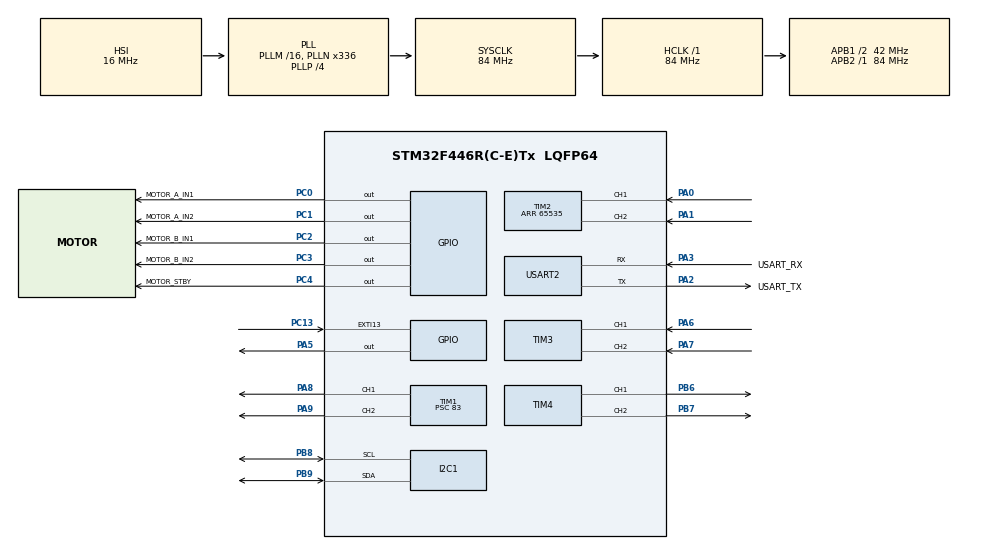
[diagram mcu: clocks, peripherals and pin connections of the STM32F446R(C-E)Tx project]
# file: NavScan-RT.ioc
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FREERTOS.Tasks01=defaultTask,24,128,StartDefaultTask,Default,NULL,Dynamic,NULL,NULL
Mcu.Family=STM32F4
Mcu.Name=STM32F446R(C-E)Tx
Mcu.Package=LQFP64
NUCLEO-F446RE.BUTTON=1
NUCLEO-F446RE.Bsp_Common_DEMO=true
NUCLEO-F446RE.LD1=true
NVIC.EXTI15_10_IRQn=true\:5\:0\:false\:false\:true\:true\:false\:true\:true
NVIC.PriorityGroup=NVIC_PRIORITYGROUP_4
NVIC.TIM6_DAC_IRQn=true\:15\:0\:false\:false\:true\:false\:false\:true\:true
NVIC.TimeBase=TIM6_DAC_IRQn
NVIC.TimeBaseIP=TIM6
PA0-WKUP.Signal=S_TIM2_CH1_ETR
PA1.Signal=S_TIM2_CH2
PA13.GPIO_Label=TMS
PA13.Mode=Serial_Wire
PA13.Signal=SYS_JTMS-SWDIO
PA14.GPIO_Label=TCK
PA14.Mode=Serial_Wire
PA14.Signal=SYS_JTCK-SWCLK
PA2.GPIO_Label=USART_TX
PA2.Mode=Asynchronous
PA2.Signal=USART2_TX
PA3.GPIO_Label=USART_RX
PA3.Mode=Asynchronous
PA3.Signal=USART2_RX
PA5.Signal=GPIO_Output
PA6.Signal=S_TIM3_CH1
PA7.Signal=S_TIM3_CH2
PA8.Signal=S_TIM1_CH1
PA9.Signal=S_TIM1_CH2
PB3.GPIO_Label=SWO
PB3.Signal=SYS_JTDO-SWO
PB6.Signal=S_TIM4_CH1
PB7.Signal=S_TIM4_CH2
PB8.Mode=I2C
PB8.Signal=I2C1_SCL
PB9.Mode=I2C
PB9.Signal=I2C1_SDA
PC0.GPIO_Label=MOTOR_A_IN1
PC0.Signal=GPIO_Output
PC1.GPIO_Label=MOTOR_A_IN2
PC1.Signal=GPIO_Output
PC13.Signal=GPXTI13
PC14-OSC32_IN.Signal=RCC_OSC32_IN
PC15-OSC32_OUT.Signal=RCC_OSC32_OUT
PC2.GPIO_Label=MOTOR_B_IN1
PC2.Signal=GPIO_Output
PC3.GPIO_Label=MOTOR_B_IN2
PC3.Signal=GPIO_Output
PC4.GPIO_Label=MOTOR_STBY
PC4.Signal=GPIO_Output
PH0-OSC_IN.Signal=RCC_OSC_IN
PH1-OSC_OUT.Signal=RCC_OSC_OUT
ProjectManager.HeapSize=0x200
ProjectManager.StackSize=0x400
ProjectManager.TargetToolchain=CMake
RCC.AHBFreq_Value=84000000
RCC.APB1CLKDivider=RCC_HCLK_DIV2
RCC.APB1Freq_Value=42000000
RCC.APB1TimFreq_Value=84000000
RCC.APB2Freq_Value=84000000
RCC.APB2TimFreq_Value=84000000
RCC.CortexFreq_Value=84000000
RCC.FLatency-AdvancedSettings=FLASH_LATENCY_2
RCC.HCLKFreq_Value=84000000
RCC.HSE_VALUE=8000000
RCC.HSI_VALUE=16000000
RCC.LSE_VALUE=32768
RCC.PLLN=336
RCC.PLLP=RCC_PLLP_DIV4
RCC.SYSCLKFreq_VALUE=84000000
RCC.SYSCLKSource=RCC_SYSCLKSOURCE_PLLCLK
RCC.USBFreq_Value=168000000
RCC.VCOOutputFreq_Value=336000000
SH.S_TIM1_CH1.0=TIM1_CH1,PWM Generation1 CH1
SH.S_TIM1_CH2.0=TIM1_CH2,PWM Generation2 CH2
SH.S_TIM2_CH1_ETR.0=TIM2_CH1,Encoder_Interface
SH.S_TIM2_CH2.0=TIM2_CH2,Encoder_Interface
SH.S_TIM3_CH1.0=TIM3_CH1,Encoder_Interface
SH.S_TIM3_CH2.0=TIM3_CH2,Encoder_Interface
SH.S_TIM4_CH1.0=TIM4_CH1,PWM Generation1 CH1
SH.S_TIM4_CH2.0=TIM4_CH2,PWM Generation2 CH2
TIM1.Channel-PWM\ Generation1\ CH1=TIM_CHANNEL_1
TIM1.Channel-PWM\ Generation2\ CH2=TIM_CHANNEL_2
TIM1.Period=19999
TIM1.Prescaler=83
TIM1.Pulse-PWM\ Generation1\ CH1=1500
TIM1.Pulse-PWM\ Generation2\ CH2=1500
TIM2.EncoderMode=TIM_ENCODERMODE_TI12
TIM2.Period=65535
TIM3.EncoderMode=TIM_ENCODERMODE_TI12
TIM4.Channel-PWM\ Generation1\ CH1=TIM_CHANNEL_1
TIM4.Channel-PWM\ Generation2\ CH2=TIM_CHANNEL_2
USART2.VirtualMode=VM_ASYNC
VP_FREERTOS_VS_CMSIS_V2.Mode=CMSIS_V2
VP_NUCLEO-F446RE_VS_BSP_COMMON.Mode=COMMON
VP_SYS_VS_tim6.Mode=TIM6
VP_TIM1_VS_ClockSourceINT.Mode=Internal
VP_TIM4_VS_ClockSourceINT.Mode=Internal
board=NUCLEO-F446RE

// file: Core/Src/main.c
/* USER CODE BEGIN Header */
/**
  ******************************************************************************
  * @file           : main.c
  * @brief          : Main program body
  ******************************************************************************
  * @attention
  *
  * Copyright (c) 2026 STMicroelectronics.
  * All rights reserved.
  *
  * This software is licensed under terms that can be found in the LICENSE file
  * in the root directory of this software component.
  * If no LICENSE file comes with this software, it is provided AS-IS.
  *
  ******************************************************************************
  */
/* USER CODE END Header */
#include "main.h"
#include "cmsis_os.h"

/* USER CODE BEGIN Includes */
#include "app.h"

/* Button state */
#define BUTTON_RELEASED                    0U
#define BUTTON_PRESSED                     1U

__IO uint32_t BspButtonState = BUTTON_RELEASED;
I2C_HandleTypeDef hi2c1;

TIM_HandleTypeDef htim1;
TIM_HandleTypeDef htim2;
TIM_HandleTypeDef htim3;
TIM_HandleTypeDef htim4;

UART_HandleTypeDef huart2;

/* Definitions for defaultTask */
osThreadId_t defaultTaskHandle;
const osThreadAttr_t defaultTask_attributes = {
  .name = "defaultTask",
  .stack_size = 128 * 4,
  .priority = (osPriority_t) osPriorityNormal,
};

void SystemClock_Config(void);
static void MX_GPIO_Init(void);
static void MX_I2C1_Init(void);
static void MX_TIM1_Init(void);
static void MX_TIM2_Init(void);
static void MX_TIM3_Init(void);
static void MX_TIM4_Init(void);
static void MX_USART2_UART_Init(void);
void StartDefaultTask(void *argument);

int main(void)
{

  /* MCU Configuration--------------------------------------------------------*/

  /* Reset of all peripherals, Initializes the Flash interface and the Systick. */
  HAL_Init();

  /* Configure the system clock */
  SystemClock_Config();

  /* Initialize all configured peripherals */
  MX_GPIO_Init();
  MX_I2C1_Init();
  MX_TIM1_Init();
  MX_TIM2_Init();
  MX_TIM3_Init();
  MX_TIM4_Init();
  MX_USART2_UART_Init();

  /* Init scheduler */
  osKernelInitialize();

  /* Create the thread(s) */
  /* creation of defaultTask */
  defaultTaskHandle = osThreadNew(StartDefaultTask, NULL, &defaultTask_attributes);

  /* Initialize leds */
  BSP_LED_Init(LED2);

  /* Initialize USER push-button, will be used to trigger an interrupt each time it's pressed.*/
  BSP_PB_Init(BUTTON_USER, BUTTON_MODE_EXTI);

  /* USER CODE END BSP */

  /* Start scheduler */
  osKernelStart();

  /* We should never get here as control is now taken by the scheduler */

  /* Infinite loop */
  /* USER CODE BEGIN WHILE */
  while (1)
  {

    /* -- Sample board code for User push-button in interrupt mode ---- */
    if (BspButtonState == BUTTON_PRESSED)
    {
      /* Update button state */
      BspButtonState = BUTTON_RELEASED;
      /* -- Sample board code to toggle leds ---- */
      BSP_LED_Toggle(LED2);
      /* ..... Perform your action ..... */
    }
    /* USER CODE END WHILE */

  }
}

void SystemClock_Config(void)
{
  RCC_OscInitTypeDef RCC_OscInitStruct = {0};
  RCC_ClkInitTypeDef RCC_ClkInitStruct = {0};

  /** Configure the main internal regulator output voltage
  */
  __HAL_RCC_PWR_CLK_ENABLE();
  __HAL_PWR_VOLTAGESCALING_CONFIG(PWR_REGULATOR_VOLTAGE_SCALE3);

  /** Initializes the RCC Oscillators according to the specified parameters
  * in the RCC_OscInitTypeDef structure.
  */
  RCC_OscInitStruct.OscillatorType = RCC_OSCILLATORTYPE_HSI;
  RCC_OscInitStruct.HSIState = RCC_HSI_ON;
  RCC_OscInitStruct.HSICalibrationValue = RCC_HSICALIBRATION_DEFAULT;
  RCC_OscInitStruct.PLL.PLLState = RCC_PLL_ON;
  RCC_OscInitStruct.PLL.PLLSource = RCC_PLLSOURCE_HSI;
  RCC_OscInitStruct.PLL.PLLM = 16;
  RCC_OscInitStruct.PLL.PLLN = 336;
  RCC_OscInitStruct.PLL.PLLP = RCC_PLLP_DIV4;
  RCC_OscInitStruct.PLL.PLLQ = 2;
  RCC_OscInitStruct.PLL.PLLR = 2;
  if (HAL_RCC_OscConfig(&RCC_OscInitStruct) != HAL_OK)
  {
    Error_Handler();
  }

  /** Initializes the CPU, AHB and APB buses clocks
  */
  RCC_ClkInitStruct.ClockType = RCC_CLOCKTYPE_HCLK|RCC_CLOCKTYPE_SYSCLK
                              |RCC_CLOCKTYPE_PCLK1|RCC_CLOCKTYPE_PCLK2;
  RCC_ClkInitStruct.SYSCLKSource = RCC_SYSCLKSOURCE_PLLCLK;
  RCC_ClkInitStruct.AHBCLKDivider = RCC_SYSCLK_DIV1;
  RCC_ClkInitStruct.APB1CLKDivider = RCC_HCLK_DIV2;
  RCC_ClkInitStruct.APB2CLKDivider = RCC_HCLK_DIV1;

  if (HAL_RCC_ClockConfig(&RCC_ClkInitStruct, FLASH_LATENCY_2) != HAL_OK)
  {
    Error_Handler();
  }
}

static void MX_I2C1_Init(void)
{

  hi2c1.Instance = I2C1;
  hi2c1.Init.ClockSpeed = 100000;
  hi2c1.Init.DutyCycle = I2C_DUTYCYCLE_2;
  hi2c1.Init.OwnAddress1 = 0;
  hi2c1.Init.AddressingMode = I2C_ADDRESSINGMODE_7BIT;
  hi2c1.Init.DualAddressMode = I2C_DUALADDRESS_DISABLE;
  hi2c1.Init.OwnAddress2 = 0;
  hi2c1.Init.GeneralCallMode = I2C_GENERALCALL_DISABLE;
  hi2c1.Init.NoStretchMode = I2C_NOSTRETCH_DISABLE;
  if (HAL_I2C_Init(&hi2c1) != HAL_OK)
  {
    Error_Handler();
  }

}

static void MX_TIM1_Init(void)
{

  TIM_ClockConfigTypeDef sClockSourceConfig = {0};
  TIM_MasterConfigTypeDef sMasterConfig = {0};
  TIM_OC_InitTypeDef sConfigOC = {0};
  TIM_BreakDeadTimeConfigTypeDef sBreakDeadTimeConfig = {0};

  htim1.Instance = TIM1;
  htim1.Init.Prescaler = 83;
  htim1.Init.CounterMode = TIM_COUNTERMODE_UP;
  htim1.Init.Period = 19999;
  htim1.Init.ClockDivision = TIM_CLOCKDIVISION_DIV1;
  htim1.Init.RepetitionCounter = 0;
  htim1.Init.AutoReloadPreload = TIM_AUTORELOAD_PRELOAD_DISABLE;
  if (HAL_TIM_Base_Init(&htim1) != HAL_OK)
  {
    Error_Handler();
  }
  sClockSourceConfig.ClockSource = TIM_CLOCKSOURCE_INTERNAL;
  if (HAL_TIM_ConfigClockSource(&htim1, &sClockSourceConfig) != HAL_OK)
  {
    Error_Handler();
  }
  if (HAL_TIM_PWM_Init(&htim1) != HAL_OK)
  {
    Error_Handler();
  }
  sMasterConfig.MasterOutputTrigger = TIM_TRGO_RESET;
  sMasterConfig.MasterSlaveMode = TIM_MASTERSLAVEMODE_DISABLE;
  if (HAL_TIMEx_MasterConfigSynchronization(&htim1, &sMasterConfig) != HAL_OK)
  {
    Error_Handler();
  }
  sConfigOC.OCMode = TIM_OCMODE_PWM1;
  sConfigOC.Pulse = 1500;
  sConfigOC.OCPolarity = TIM_OCPOLARITY_HIGH;
  sConfigOC.OCNPolarity = TIM_OCNPOLARITY_HIGH;
  sConfigOC.OCFastMode = TIM_OCFAST_DISABLE;
  sConfigOC.OCIdleState = TIM_OCIDLESTATE_RESET;
  sConfigOC.OCNIdleState = TIM_OCNIDLESTATE_RESET;
  if (HAL_TIM_PWM_ConfigChannel(&htim1, &sConfigOC, TIM_CHANNEL_1) != HAL_OK)
  {
    Error_Handler();
  }
  if (HAL_TIM_PWM_ConfigChannel(&htim1, &sConfigOC, TIM_CHANNEL_2) != HAL_OK)
  {
    Error_Handler();
  }
  sBreakDeadTimeConfig.OffStateRunMode = TIM_OSSR_DISABLE;
  sBreakDeadTimeConfig.OffStateIDLEMode = TIM_OSSI_DISABLE;
  sBreakDeadTimeConfig.LockLevel = TIM_LOCKLEVEL_OFF;
  sBreakDeadTimeConfig.DeadTime = 0;
  sBreakDeadTimeConfig.BreakState = TIM_BREAK_DISABLE;
  sBreakDeadTimeConfig.BreakPolarity = TIM_BREAKPOLARITY_HIGH;
  sBreakDeadTimeConfig.AutomaticOutput = TIM_AUTOMATICOUTPUT_DISABLE;
  if (HAL_TIMEx_ConfigBreakDeadTime(&htim1, &sBreakDeadTimeConfig) != HAL_OK)
  {
    Error_Handler();
  }
  HAL_TIM_MspPostInit(&htim1);

}

static void MX_TIM2_Init(void)
{

  TIM_Encoder_InitTypeDef sConfig = {0};
  TIM_MasterConfigTypeDef sMasterConfig = {0};

  htim2.Instance = TIM2;
  htim2.Init.Prescaler = 0;
  htim2.Init.CounterMode = TIM_COUNTERMODE_UP;
  htim2.Init.Period = 65535;
  htim2.Init.ClockDivision = TIM_CLOCKDIVISION_DIV1;
  htim2.Init.AutoReloadPreload = TIM_AUTORELOAD_PRELOAD_DISABLE;
  sConfig.EncoderMode = TIM_ENCODERMODE_TI12;
  sConfig.IC1Polarity = TIM_ICPOLARITY_RISING;
  sConfig.IC1Selection = TIM_ICSELECTION_DIRECTTI;
  sConfig.IC1Prescaler = TIM_ICPSC_DIV1;
  sConfig.IC1Filter = 0;
  sConfig.IC2Polarity = TIM_ICPOLARITY_RISING;
  sConfig.IC2Selection = TIM_ICSELECTION_DIRECTTI;
  sConfig.IC2Prescaler = TIM_ICPSC_DIV1;
  sConfig.IC2Filter = 0;
  if (HAL_TIM_Encoder_Init(&htim2, &sConfig) != HAL_OK)
  {
    Error_Handler();
  }
  sMasterConfig.MasterOutputTrigger = TIM_TRGO_RESET;
  sMasterConfig.MasterSlaveMode = TIM_MASTERSLAVEMODE_DISABLE;
  if (HAL_TIMEx_MasterConfigSynchronization(&htim2, &sMasterConfig) != HAL_OK)
  {
    Error_Handler();
  }

}

static void MX_TIM3_Init(void)
{

  TIM_Encoder_InitTypeDef sConfig = {0};
  TIM_MasterConfigTypeDef sMasterConfig = {0};

  htim3.Instance = TIM3;
  htim3.Init.Prescaler = 0;
  htim3.Init.CounterMode = TIM_COUNTERMODE_UP;
  htim3.Init.Period = 65535;
  htim3.Init.ClockDivision = TIM_CLOCKDIVISION_DIV1;
  htim3.Init.AutoReloadPreload = TIM_AUTORELOAD_PRELOAD_DISABLE;
  sConfig.EncoderMode = TIM_ENCODERMODE_TI12;
  sConfig.IC1Polarity = TIM_ICPOLARITY_RISING;
  sConfig.IC1Selection = TIM_ICSELECTION_DIRECTTI;
  sConfig.IC1Prescaler = TIM_ICPSC_DIV1;
  sConfig.IC1Filter = 0;
  sConfig.IC2Polarity = TIM_ICPOLARITY_RISING;
  sConfig.IC2Selection = TIM_ICSELECTION_DIRECTTI;
  sConfig.IC2Prescaler = TIM_ICPSC_DIV1;
  sConfig.IC2Filter = 0;
  if (HAL_TIM_Encoder_Init(&htim3, &sConfig) != HAL_OK)
  {
    Error_Handler();
  }
  sMasterConfig.MasterOutputTrigger = TIM_TRGO_RESET;
  sMasterConfig.MasterSlaveMode = TIM_MASTERSLAVEMODE_DISABLE;
  if (HAL_TIMEx_MasterConfigSynchronization(&htim3, &sMasterConfig) != HAL_OK)
  {
    Error_Handler();
  }

}

static void MX_TIM4_Init(void)
{

  TIM_ClockConfigTypeDef sClockSourceConfig = {0};
  TIM_MasterConfigTypeDef sMasterConfig = {0};
  TIM_OC_InitTypeDef sConfigOC = {0};

  htim4.Instance = TIM4;
  htim4.Init.Prescaler = 0;
  htim4.Init.CounterMode = TIM_COUNTERMODE_UP;
  htim4.Init.Period = 65535;
  htim4.Init.ClockDivision = TIM_CLOCKDIVISION_DIV1;
  htim4.Init.AutoReloadPreload = TIM_AUTORELOAD_PRELOAD_DISABLE;
  if (HAL_TIM_Base_Init(&htim4) != HAL_OK)
  {
    Error_Handler();
  }
  sClockSourceConfig.ClockSource = TIM_CLOCKSOURCE_INTERNAL;
  if (HAL_TIM_ConfigClockSource(&htim4, &sClockSourceConfig) != HAL_OK)
  {
    Error_Handler();
  }
  if (HAL_TIM_PWM_Init(&htim4) != HAL_OK)
  {
    Error_Handler();
  }
  sMasterConfig.MasterOutputTrigger = TIM_TRGO_RESET;
  sMasterConfig.MasterSlaveMode = TIM_MASTERSLAVEMODE_DISABLE;
  if (HAL_TIMEx_MasterConfigSynchronization(&htim4, &sMasterConfig) != HAL_OK)
  {
    Error_Handler();
  }
  sConfigOC.OCMode = TIM_OCMODE_PWM1;
  sConfigOC.Pulse = 0;
  sConfigOC.OCPolarity = TIM_OCPOLARITY_HIGH;
  sConfigOC.OCFastMode = TIM_OCFAST_DISABLE;
  if (HAL_TIM_PWM_ConfigChannel(&htim4, &sConfigOC, TIM_CHANNEL_1) != HAL_OK)
  {
    Error_Handler();
  }
  if (HAL_TIM_PWM_ConfigChannel(&htim4, &sConfigOC, TIM_CHANNEL_2) != HAL_OK)
  {
    Error_Handler();
  }
  HAL_TIM_MspPostInit(&htim4);

}

static void MX_USART2_UART_Init(void)
{

  huart2.Instance = USART2;
  huart2.Init.BaudRate = 115200;
  huart2.Init.WordLength = UART_WORDLENGTH_8B;
  huart2.Init.StopBits = UART_STOPBITS_1;
  huart2.Init.Parity = UART_PARITY_NONE;
  huart2.Init.Mode = UART_MODE_TX_RX;
  huart2.Init.HwFlowCtl = UART_HWCONTROL_NONE;
  huart2.Init.OverSampling = UART_OVERSAMPLING_16;
  if (HAL_UART_Init(&huart2) != HAL_OK)
  {
    Error_Handler();
  }

}

static void MX_GPIO_Init(void)
{
  GPIO_InitTypeDef GPIO_InitStruct = {0};

  /* GPIO Ports Clock Enable */
  __HAL_RCC_GPIOC_CLK_ENABLE();
  __HAL_RCC_GPIOH_CLK_ENABLE();
  __HAL_RCC_GPIOA_CLK_ENABLE();
  __HAL_RCC_GPIOB_CLK_ENABLE();

  /*Configure GPIO pin Output Level */
  HAL_GPIO_WritePin(GPIOC, MOTOR_A_IN1_Pin|MOTOR_A_IN2_Pin|MOTOR_B_IN1_Pin|MOTOR_B_IN2_Pin
                          |MOTOR_STBY_Pin, GPIO_PIN_RESET);

  /*Configure GPIO pins : MOTOR_A_IN1_Pin MOTOR_A_IN2_Pin MOTOR_B_IN1_Pin MOTOR_B_IN2_Pin
                           MOTOR_STBY_Pin */
  GPIO_InitStruct.Pin = MOTOR_A_IN1_Pin|MOTOR_A_IN2_Pin|MOTOR_B_IN1_Pin|MOTOR_B_IN2_Pin
                          |MOTOR_STBY_Pin;
  GPIO_InitStruct.Mode = GPIO_MODE_OUTPUT_PP;
  GPIO_InitStruct.Pull = GPIO_NOPULL;
  GPIO_InitStruct.Speed = GPIO_SPEED_FREQ_LOW;
  HAL_GPIO_Init(GPIOC, &GPIO_InitStruct);

}

void StartDefaultTask(void *argument)
{
  /* USER CODE BEGIN 5 */
  (void)argument;
  /* Enter the C++ application from this running FreeRTOS task. */
  app_run();
  /* USER CODE END 5 */
}

void HAL_TIM_PeriodElapsedCallback(TIM_HandleTypeDef *htim)
{
  if (htim->Instance == TIM6)
  {
    HAL_IncTick();
  }
}

/**
  * @brief EXTI line detection callbacks
  * @param GPIO_Pin: Specifies the pins connected EXTI line
  * @retval None
  */
void HAL_GPIO_EXTI_Callback(uint16_t GPIO_Pin)
{
  if(GPIO_Pin==USER_BUTTON_PIN)
  {
    BspButtonState = BUTTON_PRESSED;
  }
}

void Error_Handler(void)
{
  __disable_irq();
  while (1)
  {
  }
}
